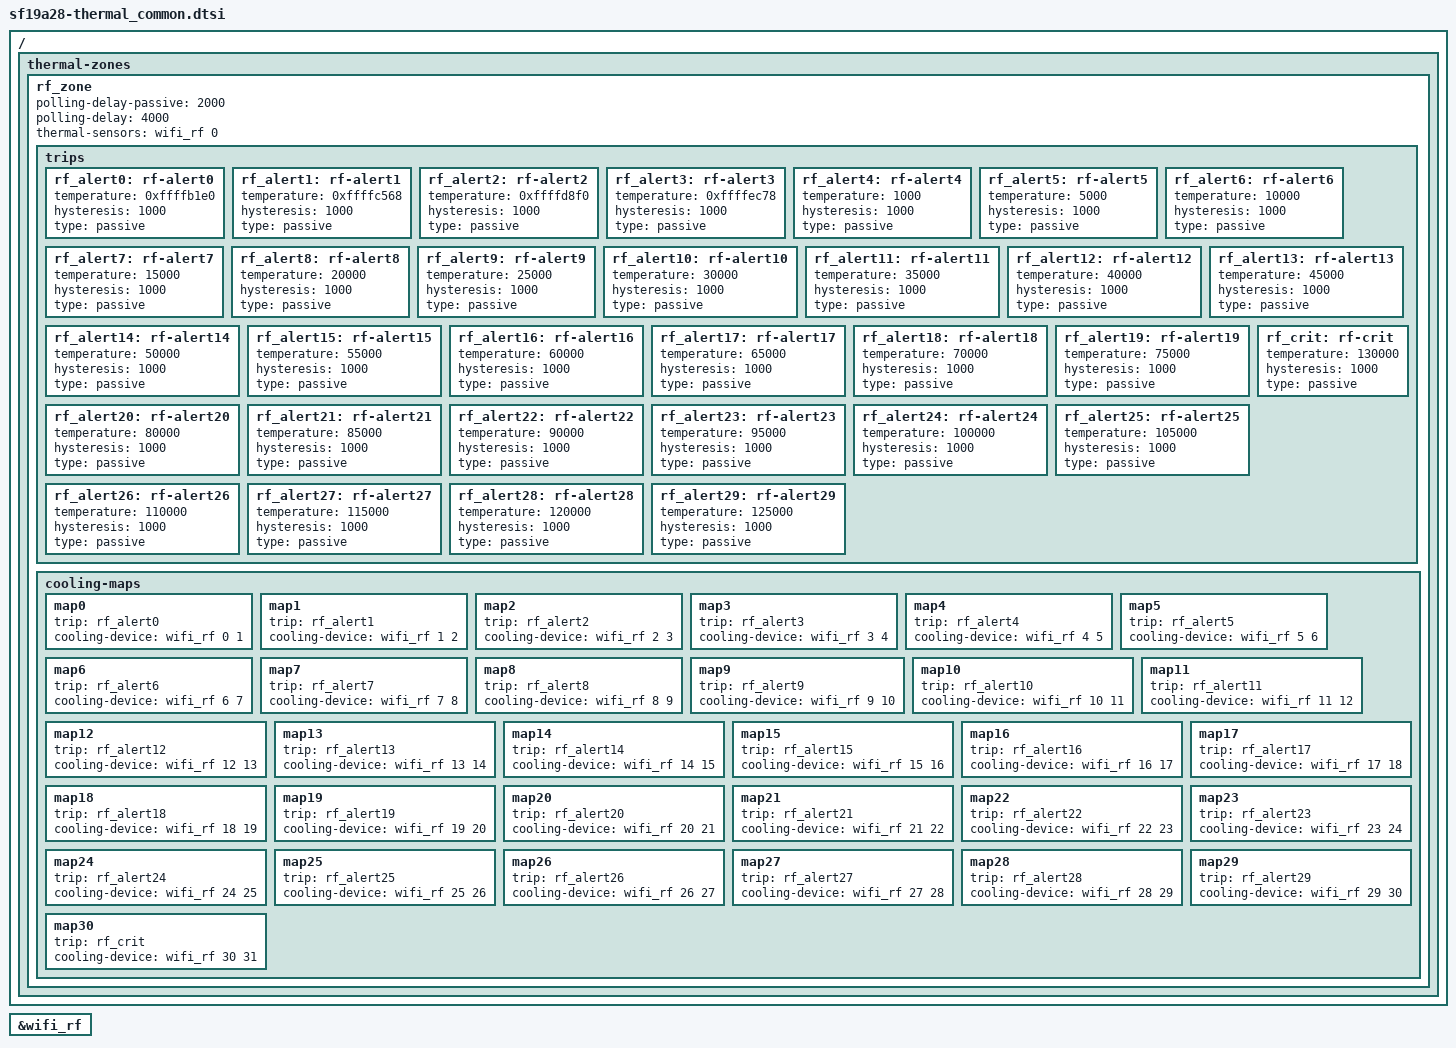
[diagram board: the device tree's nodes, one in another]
/*
 * Device Tree Source for Siflower A18 SoC thermal
 *
 * Copyright (C) 2017 Shanghai Siflower Communication Technology Co., Ltd.
 * Author: Qi Zhang <qi.zhang@siflower.com.cn>
 *
 * This file is licensed under the terms of the GNU General Public License
 * version 2.  This program is licensed "as is" without any warranty of any
 * kind, whether express or implied.
 */

#include <dt-bindings/thermal/thermal.h>

&wifi_rf {
	#thermal-sensor-cells = <1>;
};

&wifi_rf {
	#cooling-cells = <2>;
};
/*
&cpu0 {
	#cooling-cells = <2>;
};
 */
/ {
	thermal-zones {
rf_zone: rf_zone {
			 polling-delay-passive = <2000>; /* milliseconds */
			 polling-delay = <4000>; /* milliseconds */
			 /* sensor	ID */
			 thermal-sensors = <&wifi_rf	0>;

			 trips {
 /*#cpu_alert0: cpu_alert {
				#temperature = <90000>; /* millicelsius */
				 /*        hysteresis = <2000>; /* millicelsius */
				 /*        type = "passive";
						   }; */
rf_alert0: rf-alert0 {
			   temperature = <0xffffb1e0>; /* millicelsius */
			   hysteresis = <1000>; /* millicelsius */
			   type = "passive";
		   };
rf_alert1: rf-alert1 {
			   temperature = <0xffffc568>; /* millicelsius */
			   hysteresis = <1000>; /* millicelsius */
			   type = "passive";
		   };

rf_alert2: rf-alert2 {
			   temperature = <0xffffd8f0>; /* millicelsius */
			   hysteresis = <1000>; /* millicelsius */
			   type = "passive";
		   };
rf_alert3: rf-alert3 {
			   temperature = <0xffffec78>; /* millicelsius */
			   hysteresis = <1000>; /* millicelsius */
			   type = "passive";
		   };
rf_alert4: rf-alert4 {
			   temperature = <1000>; /* millicelsius */
			   hysteresis = <1000>; /* millicelsius */
			   type = "passive";
		   };
rf_alert5: rf-alert5 {
			   temperature = <5000>; /* millicelsius */
			   hysteresis = <1000>; /* millicelsius */
			   type = "passive";
		   };
rf_alert6: rf-alert6 {
			   temperature = <10000>; /* millicelsius */
			   hysteresis = <1000>; /* millicelsius */
			   type = "passive";
		   };
rf_alert7: rf-alert7 {
			   temperature = <15000>; /* millicelsius */
			   hysteresis = <1000>; /* millicelsius */
			   type = "passive";
		   };
rf_alert8: rf-alert8 {
			   temperature = <20000>; /* millicelsius */
			   hysteresis = <1000>; /* millicelsius */
			   type = "passive";
		   };
rf_alert9: rf-alert9 {
			   temperature = <25000>; /* millicelsius */
			   hysteresis = <1000>; /* millicelsius */
			   type = "passive";
		   };
rf_alert10: rf-alert10 {
			   temperature = <30000>; /* millicelsius */
			   hysteresis = <1000>; /* millicelsius */
			   type = "passive";
		   };
rf_alert11: rf-alert11 {
			   temperature = <35000>; /* millicelsius */
			   hysteresis = <1000>; /* millicelsius */
			   type = "passive";
		   };

rf_alert12: rf-alert12 {
			   temperature = <40000>; /* millicelsius */
			   hysteresis = <1000>; /* millicelsius */
			   type = "passive";
		   };
rf_alert13: rf-alert13 {
			   temperature = <45000>; /* millicelsius */
			   hysteresis = <1000>; /* millicelsius */
			   type = "passive";
		   };
rf_alert14: rf-alert14 {
			   temperature = <50000>; /* millicelsius */
			   hysteresis = <1000>; /* millicelsius */
			   type = "passive";
		   };
rf_alert15: rf-alert15 {
			   temperature = <55000>; /* millicelsius */
			   hysteresis = <1000>; /* millicelsius */
			   type = "passive";
		   };
rf_alert16: rf-alert16 {
			   temperature = <60000>; /* millicelsius */
			   hysteresis = <1000>; /* millicelsius */
			   type = "passive";
		   };
rf_alert17: rf-alert17 {
			   temperature = <65000>; /* millicelsius */
			   hysteresis = <1000>; /* millicelsius */
			   type = "passive";
		   };
rf_alert18: rf-alert18 {
			   temperature = <70000>; /* millicelsius */
			   hysteresis = <1000>; /* millicelsius */
			   type = "passive";
		   };
rf_alert19: rf-alert19 {
			   temperature = <75000>; /* millicelsius */
			   hysteresis = <1000>; /* millicelsius */
			   type = "passive";
		   };
rf_alert20: rf-alert20 {
			   temperature = <80000>; /* millicelsius */
			   hysteresis = <1000>; /* millicelsius */
			   type = "passive";
		   };
rf_alert21: rf-alert21 {
			   temperature = <85000>; /* millicelsius */
			   hysteresis = <1000>; /* millicelsius */
			   type = "passive";
		   };
rf_alert22: rf-alert22 {
			   temperature = <90000>; /* millicelsius */
			   hysteresis = <1000>; /* millicelsius */
			   type = "passive";
		   };
rf_alert23: rf-alert23 {
			   temperature = <95000>; /* millicelsius */
			   hysteresis = <1000>; /* millicelsius */
			   type = "passive";
		   };
rf_alert24: rf-alert24 {
			   temperature = <100000>; /* millicelsius */
			   hysteresis = <1000>; /* millicelsius */
			   type = "passive";
		   };
rf_alert25: rf-alert25 {
			   temperature = <105000>; /* millicelsius */
			   hysteresis = <1000>; /* millicelsius */
			   type = "passive";
		   };
rf_alert26: rf-alert26 {
			   temperature = <110000>; /* millicelsius */
			   hysteresis = <1000>; /* millicelsius */
			   type = "passive";
		   };
rf_alert27: rf-alert27 {
			   temperature = <115000>; /* millicelsius */
			   hysteresis = <1000>; /* millicelsius */
			   type = "passive";
		   };
rf_alert28: rf-alert28 {
			   temperature = <120000>; /* millicelsius */
			   hysteresis = <1000>; /* millicelsius */
			   type = "passive";
		   };
rf_alert29: rf-alert29 {
			   temperature = <125000>; /* millicelsius */
			   hysteresis = <1000>; /* millicelsius */
			   type = "passive";
		   };
rf_crit: rf-crit {
			 temperature = <130000>; /* millicelsius */
			 hysteresis = <1000>; /* millicelsius */
			 type = "passive";
		 };
		 /*
cpu_crit: cpu_crit {
temperature = <125000>; /* millicelsius */
		 /*        hysteresis = <2000>; /* millicelsius */
		 /*        type = "critical";
				   };*/
			 };

			 cooling-maps {
				 /*
					cpu0 {
					trip = <&cpu_alert0>;
					cooling-device = <&cpu0 THERMAL_NO_LIMIT THERMAL_NO_LIMIT>;
					};*/
				 map0 {
					 trip = <&rf_alert0>;
					 cooling-device = <&wifi_rf 0 1>;
				 };
				 map1 {
					 trip = <&rf_alert1>;
					 cooling-device = <&wifi_rf 1 2>;
				 };
				 map2 {
					 trip = <&rf_alert2>;
					 cooling-device = <&wifi_rf 2 3>;
				 };
				 map3 {
					 trip = <&rf_alert3>;
					 cooling-device = <&wifi_rf 3 4>;
				 };
				 map4 {
					 trip = <&rf_alert4>;
					 cooling-device = <&wifi_rf 4 5>;
				 };
				 map5 {
					 trip = <&rf_alert5>;
					 cooling-device = <&wifi_rf 5 6>;
				 };
				 map6 {
					 trip = <&rf_alert6>;
					 cooling-device = <&wifi_rf 6 7>;
				 };
				 map7 {
					 trip = <&rf_alert7>;
					 cooling-device = <&wifi_rf 7 8>;
				 };
				 map8 {
					 trip = <&rf_alert8>;
					 cooling-device = <&wifi_rf 8 9>;
				 };
				map9 {
					 trip = <&rf_alert9>;
					 cooling-device = <&wifi_rf 9 10>;
				 };
             	map10 {
					 trip = <&rf_alert10>;
					 cooling-device = <&wifi_rf 10 11>;
				 };
				map11 {
					 trip = <&rf_alert11>;
					 cooling-device = <&wifi_rf 11 12>;
				 };
				 map12 {
					 trip = <&rf_alert12>;
					 cooling-device = <&wifi_rf 12 13>;
				 };
				 map13 {
					 trip = <&rf_alert13>;
					 cooling-device = <&wifi_rf 13 14>;
				 };
				 map14 {
					 trip = <&rf_alert14>;
					 cooling-device = <&wifi_rf 14 15>;
				 };
				 map15 {
					 trip = <&rf_alert15>;
					 cooling-device = <&wifi_rf 15 16>;
				 };
				 map16 {
					 trip = <&rf_alert16>;
					 cooling-device = <&wifi_rf 16 17>;
				 };
				 map17 {
					 trip = <&rf_alert17>;
					 cooling-device = <&wifi_rf 17 18>;
				 };
				 map18 {
					 trip = <&rf_alert18>;
					 cooling-device = <&wifi_rf 18 19>;
				 };
				 map19 {
					 trip = <&rf_alert19>;
					 cooling-device = <&wifi_rf 19 20>;
				 };
   				 map20 {
					 trip = <&rf_alert20>;
					 cooling-device = <&wifi_rf 20 21>;
				 };
				 map21 {
					 trip = <&rf_alert21>;
					 cooling-device = <&wifi_rf 21 22>;
				 };
				 map22 {
					 trip = <&rf_alert22>;
					 cooling-device = <&wifi_rf 22 23>;
				 };
				 map23 {
					 trip = <&rf_alert23>;
					 cooling-device = <&wifi_rf 23 24>;
				 };
				 map24 {
					 trip = <&rf_alert24>;
					 cooling-device = <&wifi_rf 24 25>;
				 };
				 map25 {
					 trip = <&rf_alert25>;
					 cooling-device = <&wifi_rf 25 26>;
				 };
				 map26 {
					 trip = <&rf_alert26>;
					 cooling-device = <&wifi_rf 26 27>;
				 };
				 map27 {
					 trip = <&rf_alert27>;
					 cooling-device = <&wifi_rf 27 28>;
				 };
				 map28 {
					 trip = <&rf_alert28>;
					 cooling-device = <&wifi_rf 28 29>;
				 };
				 map29 {
					 trip = <&rf_alert29>;
					 cooling-device = <&wifi_rf 29 30>;
				 };
				 map30 {
					 trip = <&rf_crit>;
					 cooling-device = <&wifi_rf 30 31>;
				 };
			 };
		 };
	};
};
